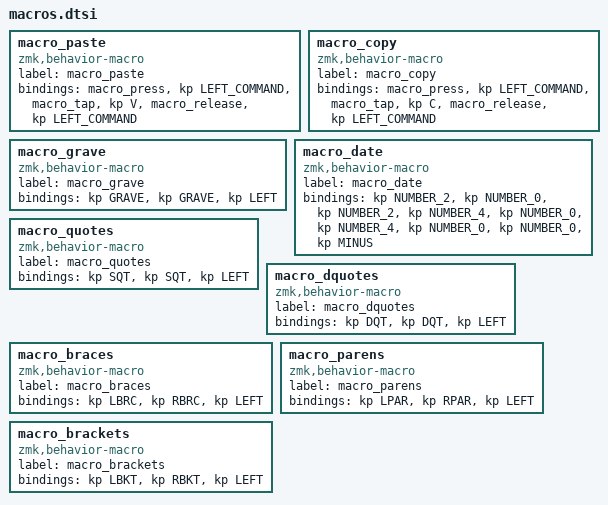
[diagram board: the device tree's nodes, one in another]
macro_paste: macro_paste{
               compatible = "zmk,behavior-macro";
               label = "macro_paste";
               #binding-cells = <0>;
               bindings = <&macro_press &kp LEFT_COMMAND>
                 , <&macro_tap &kp V>
                 , <&macro_release &kp LEFT_COMMAND>
                 ;
             };

macro_copy: macro_copy{
              compatible = "zmk,behavior-macro";
              label = "macro_copy";
               #binding-cells = <0>;
              bindings = <&macro_press &kp LEFT_COMMAND>
                , <&macro_tap &kp C>
                , <&macro_release &kp LEFT_COMMAND>
                ;
            };

macro_grave: macro_grave{
               compatible = "zmk,behavior-macro";
               label = "macro_grave";
               #binding-cells = <0>;
               bindings = <&kp GRAVE>, <&kp GRAVE>, <&kp LEFT>;
             };

macro_date: macro_date{
              compatible = "zmk,behavior-macro";
              label = "macro_date";
               #binding-cells = <0>;
              bindings = <&kp NUMBER_2>, <&kp NUMBER_0>, <&kp NUMBER_2>, <&kp NUMBER_4>, <&kp NUMBER_0>, <&kp NUMBER_4>, <&kp NUMBER_0>, <&kp NUMBER_0>, <&kp MINUS>;
            };

macro_quotes: macro_quotes{
                compatible = "zmk,behavior-macro";
                label = "macro_quotes";
               #binding-cells = <0>;
                bindings = <&kp SQT>, <&kp SQT>, <&kp LEFT>;
              };
              
macro_dquotes: macro_dquotes{
                 compatible = "zmk,behavior-macro";
                 label = "macro_dquotes";
               #binding-cells = <0>;
                 bindings = <&kp DQT>, <&kp DQT>, <&kp LEFT>;
               };

macro_braces: macro_braces{
                compatible = "zmk,behavior-macro";
                label = "macro_braces";
               #binding-cells = <0>;
                bindings = <&kp LBRC>, <&kp RBRC>, <&kp LEFT>;
              };

macro_parens: macro_parens{
                compatible = "zmk,behavior-macro";
                label = "macro_parens";
               #binding-cells = <0>;
                bindings = <&kp LPAR>, <&kp RPAR>, <&kp LEFT>;
              };

macro_brackets: macro_brackets{
                  compatible = "zmk,behavior-macro";
                  label = "macro_brackets";
               #binding-cells = <0>;
                  bindings = <&kp LBKT>, <&kp RBKT>, <&kp LEFT>;
};
